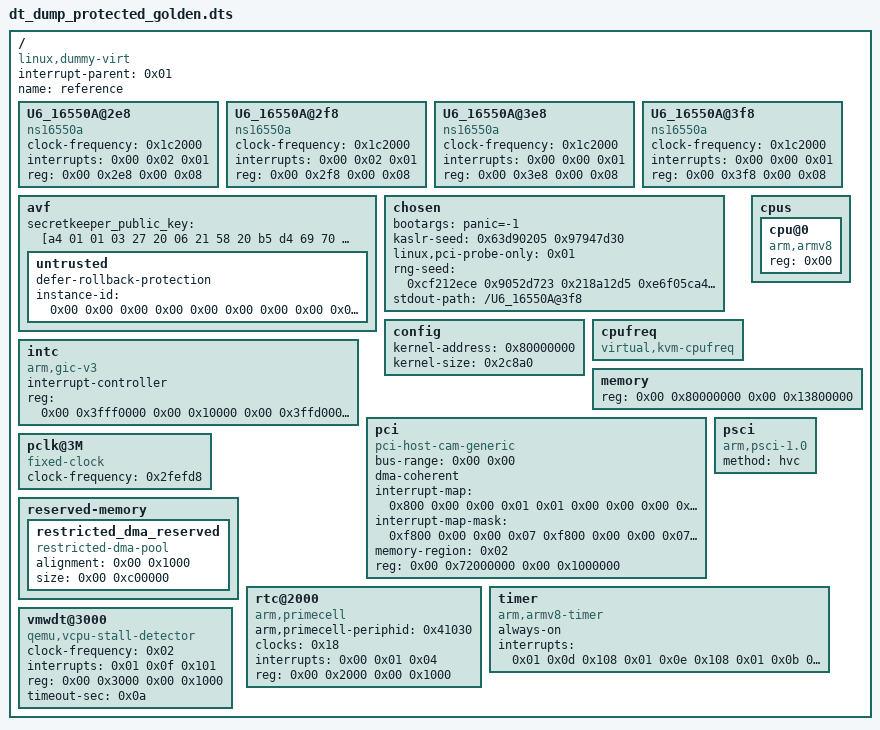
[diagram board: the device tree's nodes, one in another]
/dts-v1/;

/ {
	#address-cells = <0x02>;
	#size-cells = <0x02>;
	compatible = "linux,dummy-virt";
	interrupt-parent = <0x01>;
	name = "reference";

	U6_16550A@2e8 {
		clock-frequency = <0x1c2000>;
		compatible = "ns16550a";
		interrupts = <0x00 0x02 0x01>;
		reg = <0x00 0x2e8 0x00 0x08>;
	};

	U6_16550A@2f8 {
		clock-frequency = <0x1c2000>;
		compatible = "ns16550a";
		interrupts = <0x00 0x02 0x01>;
		reg = <0x00 0x2f8 0x00 0x08>;
	};

	U6_16550A@3e8 {
		clock-frequency = <0x1c2000>;
		compatible = "ns16550a";
		interrupts = <0x00 0x00 0x01>;
		reg = <0x00 0x3e8 0x00 0x08>;
	};

	U6_16550A@3f8 {
		clock-frequency = <0x1c2000>;
		compatible = "ns16550a";
		interrupts = <0x00 0x00 0x01>;
		reg = <0x00 0x3f8 0x00 0x08>;
	};

	__symbols__ {
		intc = "/intc";
	};

	avf {
		secretkeeper_public_key = [a4 01 01 03 27 20 06 21 58 20 b5 d4 69 70 1d a4 d9 06 a3 70 4e d4 3e 2f 62 f1 2f 80 ba 27 ef 19 b6 21 c2 7a 98 4a 04 a5 f2 b0];

		untrusted {
			defer-rollback-protection;
			instance-id = <0x00 0x00 0x00 0x00 0x00 0x00 0x00 0x00 0x00 0x00 0x00 0x00 0x00 0x00 0x00 0x00>;
		};
	};

	chosen {
		bootargs = "panic=-1";
		kaslr-seed = <0x63d90205 0x97947d30>;
		linux,pci-probe-only = <0x01>;
		rng-seed = <0xcf212ece 0x9052d723 0x218a12d5 0xe6f05ca4 0xe80d2c32 0xf4c7a159 0xecd57cf7 0x6c72d99f 0xf20f7b86 0xcfa447e9 0x185e28e9 0xfb9770d1 0x9899bfa6 0x34cea1df 0x9fa90f7 0x3170842b 0x4c85e174 0xd2c53de8 0x1c4b05b1 0x493a9f8b 0xde780976 0xcc022801 0xa14b8b28 0x5dd0a2c6 0x1d499138 0xcb67b911 0x464a1b95 0x83d90d7c 0xd2ecaf64 0x16152f81 0x7074bcac 0x802b2de4 0x42abd96 0x6bcb6633 0x3f963700 0xd089172d 0xf5b29da 0x28839c6f 0x775fb7a 0xd797ecc5 0xffc8d985 0x89cfb692 0xfd665800 0xfa9ea7b7 0x5e861025 0xbb984db0 0xbc53e55 0x8473f169 0xd1a6b4bc 0x2fd95fbc 0x814f14e5 0x84d1894 0xaa82c5c3 0x9a56b42 0x574b9a23 0x4b5a58b 0xbd979463 0x226ee627 0x418102b9 0x97dcbf41 0x49fd24eb 0xe7b055a1 0xe86e3e6e 0x93d07341>;
		stdout-path = "/U6_16550A@3f8";
	};

	config {
		kernel-address = <0x80000000>;
		kernel-size = <0x2c8a0>;
	};

	cpufreq {
		compatible = "virtual,kvm-cpufreq";
	};

	cpus {
		#address-cells = <0x01>;
		#size-cells = <0x00>;

		cpu@0 {
			compatible = "arm,armv8";
			device_type = "cpu";
			phandle = <0x100>;
			reg = <0x00>;
		};
	};

	intc {
		#address-cells = <0x02>;
		#interrupt-cells = <0x03>;
		#size-cells = <0x02>;
		compatible = "arm,gic-v3";
		interrupt-controller;
		phandle = <0x01>;
		reg = <0x00 0x3fff0000 0x00 0x10000 0x00 0x3ffd0000 0x00 0x20000>;
	};

	memory {
		device_type = "memory";
		reg = <0x00 0x80000000 0x00 0x13800000>;
	};

	pci {
		#address-cells = <0x03>;
		#interrupt-cells = <0x01>;
		#size-cells = <0x02>;
		bus-range = <0x00 0x00>;
		compatible = "pci-host-cam-generic";
		device_type = "pci";
		dma-coherent;
		interrupt-map = <0x800 0x00 0x00 0x01 0x01 0x00 0x00 0x00 0x04 0x04 0x1000 0x00 0x00 0x01 0x01 0x00 0x00 0x00 0x05 0x04 0x1800 0x00 0x00 0x01 0x01 0x00 0x00 0x00 0x06 0x04 0x2000 0x00 0x00 0x01 0x01 0x00 0x00 0x00 0x07 0x04 0x2800 0x00 0x00 0x01 0x01 0x00 0x00 0x00 0x08 0x04 0x3000 0x00 0x00 0x01 0x01 0x00 0x00 0x00 0x09 0x04 0x3800 0x00 0x00 0x01 0x01 0x00 0x00 0x00 0x0a 0x04>;
		interrupt-map-mask = <0xf800 0x00 0x00 0x07 0xf800 0x00 0x00 0x07 0xf800 0x00 0x00 0x07 0xf800 0x00 0x00 0x07 0xf800 0x00 0x00 0x07 0xf800 0x00 0x00 0x07 0xf800 0x00 0x00 0x07>;
		memory-region = <0x02>;
		ranges = <0x3000000 0x00 0x70000000 0x00 0x70000000 0x00 0x2000000 0x43000000 0x00 0x94000000 0x00 0x94000000 0xff 0x6c000000>;
		reg = <0x00 0x72000000 0x00 0x1000000>;
	};

	pclk@3M {
		#clock-cells = <0x00>;
		clock-frequency = <0x2fefd8>;
		compatible = "fixed-clock";
		phandle = <0x18>;
	};

	psci {
		compatible = "arm,psci-1.0\0arm,psci-0.2";
		method = "hvc";
	};

	reserved-memory {
		#address-cells = <0x02>;
		#size-cells = <0x02>;
		ranges;

		restricted_dma_reserved {
			alignment = <0x00 0x1000>;
			compatible = "restricted-dma-pool";

			phandle = <0x02>;
			size = <0x00 0xc00000>;
		};
	};

	rtc@2000 {
		arm,primecell-periphid = <0x41030>;
		clock-names = "apb_pclk";
		clocks = <0x18>;
		compatible = "arm,primecell";
		interrupts = <0x00 0x01 0x04>;
		reg = <0x00 0x2000 0x00 0x1000>;
	};

	timer {
		always-on;
		compatible = "arm,armv8-timer";
		interrupts = <0x01 0x0d 0x108 0x01 0x0e 0x108 0x01 0x0b 0x108 0x01 0x0a 0x108>;
	};

	vmwdt@3000 {
		clock-frequency = <0x02>;
		compatible = "qemu,vcpu-stall-detector";
		interrupts = <0x01 0x0f 0x101>;
		reg = <0x00 0x3000 0x00 0x1000>;
		timeout-sec = <0x0a>;
	};
};
